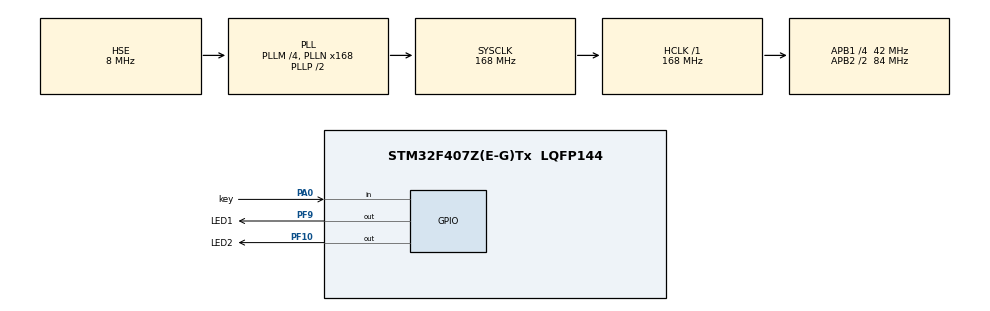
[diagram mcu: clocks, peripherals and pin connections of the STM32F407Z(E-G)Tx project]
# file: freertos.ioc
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FREERTOS.Queues01=message,16,uint16_t,0,Dynamic,NULL,NULL
FREERTOS.Tasks01=key,24,128,keyfunction,Default,NULL,Dynamic,NULL,NULL;led,8,128,ledfunction,Default,NULL,Dynamic,NULL,NULL
Mcu.Family=STM32F4
Mcu.Name=STM32F407Z(E-G)Tx
Mcu.Package=LQFP144
NVIC.PriorityGroup=NVIC_PRIORITYGROUP_4
NVIC.TIM7_IRQn=true\:0\:0\:false\:false\:true\:false\:false\:true
NVIC.TimeBase=TIM7_IRQn
NVIC.TimeBaseIP=TIM7
PA0-WKUP.GPIO_Label=key
PA0-WKUP.Signal=GPIO_Input
PA13.Mode=Serial_Wire
PA13.Signal=SYS_JTMS-SWDIO
PA14.Mode=Serial_Wire
PA14.Signal=SYS_JTCK-SWCLK
PF10.GPIO_Label=LED2
PF10.Signal=GPIO_Output
PF9.GPIO_Label=LED1
PF9.Signal=GPIO_Output
PH0-OSC_IN.Mode=HSE-External-Oscillator
PH0-OSC_IN.Signal=RCC_OSC_IN
PH1-OSC_OUT.Mode=HSE-External-Oscillator
PH1-OSC_OUT.Signal=RCC_OSC_OUT
ProjectManager.HeapSize=0x200
ProjectManager.StackSize=0x400
ProjectManager.TargetToolchain=STM32CubeIDE
RCC.48MHZClocksFreq_Value=84000000
RCC.AHBFreq_Value=168000000
RCC.APB1CLKDivider=RCC_HCLK_DIV4
RCC.APB1Freq_Value=42000000
RCC.APB1TimFreq_Value=84000000
RCC.APB2CLKDivider=RCC_HCLK_DIV2
RCC.APB2Freq_Value=84000000
RCC.APB2TimFreq_Value=168000000
RCC.CortexFreq_Value=168000000
RCC.HCLKFreq_Value=168000000
RCC.HSE_VALUE=8000000
RCC.HSI_VALUE=16000000
RCC.LSE_VALUE=32768
RCC.PLLM=4
RCC.PLLN=168
RCC.PLLSourceVirtual=RCC_PLLSOURCE_HSE
RCC.SYSCLKFreq_VALUE=168000000
RCC.SYSCLKSource=RCC_SYSCLKSOURCE_PLLCLK
RCC.VCOOutputFreq_Value=336000000
VP_FREERTOS_VS_CMSIS_V2.Mode=CMSIS_V2
VP_RTC_VS_RTC_Activate.Mode=RTC_Enabled
VP_SYS_VS_tim7.Mode=TIM7
board=custom

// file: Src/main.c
/* USER CODE BEGIN Header */
/**
  ******************************************************************************
  * @file           : main.c
  * @brief          : Main program body
  ******************************************************************************
  * @attention
  *
  * <h2><center>&copy; Copyright (c) 2019 STMicroelectronics.
  * All rights reserved.</center></h2>
  *
  * This software component is licensed by ST under Ultimate Liberty license
  * SLA0044, the "License"; You may not use this file except in compliance with
  * the License. You may obtain a copy of the License at:
  *                             www.st.com/SLA0044
  *
  ******************************************************************************
  */
/* USER CODE END Header */

#include "main.h"
#include "cmsis_os.h"
#include "rtc.h"
#include "gpio.h"

void SystemClock_Config(void);
void MX_FREERTOS_Init(void);

int main(void)
{

  /* MCU Configuration--------------------------------------------------------*/

  /* Reset of all peripherals, Initializes the Flash interface and the Systick. */
  HAL_Init();

  /* Configure the system clock */
  SystemClock_Config();

  /* Initialize all configured peripherals */
  MX_GPIO_Init();
  MX_RTC_Init();

  /* Call init function for freertos objects (in freertos.c) */
  MX_FREERTOS_Init();

  /* Start scheduler */
  osKernelStart();

  /* We should never get here as control is now taken by the scheduler */

  /* Infinite loop */
  while (1)
  {

  }
}

void SystemClock_Config(void)
{
  RCC_OscInitTypeDef RCC_OscInitStruct = {0};
  RCC_ClkInitTypeDef RCC_ClkInitStruct = {0};
  RCC_PeriphCLKInitTypeDef PeriphClkInitStruct = {0};

  /** Configure the main internal regulator output voltage
  */
  __HAL_RCC_PWR_CLK_ENABLE();
  __HAL_PWR_VOLTAGESCALING_CONFIG(PWR_REGULATOR_VOLTAGE_SCALE1);
  /** Initializes the CPU, AHB and APB busses clocks
  */
  RCC_OscInitStruct.OscillatorType = RCC_OSCILLATORTYPE_LSI|RCC_OSCILLATORTYPE_HSE;
  RCC_OscInitStruct.HSEState = RCC_HSE_ON;
  RCC_OscInitStruct.LSIState = RCC_LSI_ON;
  RCC_OscInitStruct.PLL.PLLState = RCC_PLL_ON;
  RCC_OscInitStruct.PLL.PLLSource = RCC_PLLSOURCE_HSE;
  RCC_OscInitStruct.PLL.PLLM = 4;
  RCC_OscInitStruct.PLL.PLLN = 168;
  RCC_OscInitStruct.PLL.PLLP = RCC_PLLP_DIV2;
  RCC_OscInitStruct.PLL.PLLQ = 4;
  if (HAL_RCC_OscConfig(&RCC_OscInitStruct) != HAL_OK)
  {
    Error_Handler();
  }
  /** Initializes the CPU, AHB and APB busses clocks
  */
  RCC_ClkInitStruct.ClockType = RCC_CLOCKTYPE_HCLK|RCC_CLOCKTYPE_SYSCLK
                              |RCC_CLOCKTYPE_PCLK1|RCC_CLOCKTYPE_PCLK2;
  RCC_ClkInitStruct.SYSCLKSource = RCC_SYSCLKSOURCE_PLLCLK;
  RCC_ClkInitStruct.AHBCLKDivider = RCC_SYSCLK_DIV1;
  RCC_ClkInitStruct.APB1CLKDivider = RCC_HCLK_DIV4;
  RCC_ClkInitStruct.APB2CLKDivider = RCC_HCLK_DIV2;

  if (HAL_RCC_ClockConfig(&RCC_ClkInitStruct, FLASH_LATENCY_5) != HAL_OK)
  {
    Error_Handler();
  }
  PeriphClkInitStruct.PeriphClockSelection = RCC_PERIPHCLK_RTC;
  PeriphClkInitStruct.RTCClockSelection = RCC_RTCCLKSOURCE_LSI;
  if (HAL_RCCEx_PeriphCLKConfig(&PeriphClkInitStruct) != HAL_OK)
  {
    Error_Handler();
  }
}

void HAL_TIM_PeriodElapsedCallback(TIM_HandleTypeDef *htim)
{
  if (htim->Instance == TIM7) {
    HAL_IncTick();
  }
}

void Error_Handler(void)
{
}

/************************ (C) COPYRIGHT STMicroelectronics *****END OF FILE****/

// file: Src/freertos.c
/* USER CODE BEGIN Header */
/**
  ******************************************************************************
  * File Name          : freertos.c
  * Description        : Code for freertos applications
  ******************************************************************************
  * @attention
  *
  * <h2><center>&copy; Copyright (c) 2019 STMicroelectronics.
  * All rights reserved.</center></h2>
  *
  * This software component is licensed by ST under Ultimate Liberty license
  * SLA0044, the "License"; You may not use this file except in compliance with
  * the License. You may obtain a copy of the License at:
  *                             www.st.com/SLA0044
  *
  ******************************************************************************
  */
/* USER CODE END Header */

#include "FreeRTOS.h"
#include "task.h"
#include "main.h"
#include "cmsis_os.h"

osThreadId_t keyHandle;
osThreadId_t led1Handle;
osThreadId_t led2Handle;
osMessageQueueId_t messageHandle;

void keyfunction(void *argument); // for v2
void led1function(void *argument); // for v2
void led2function(void *argument); // for v2

void MX_FREERTOS_Init(void); /* (MISRA C 2004 rule 8.1) */

void MX_FREERTOS_Init(void) {
osKernelInitialize(); // Initialize CMSIS-RTOS

  /* Create the queue(s) */
  /* definition and creation of message */
  const osMessageQueueAttr_t message_attributes = {
    .name = "message"
  };
  messageHandle = osMessageQueueNew (16, sizeof(uint16_t), &message_attributes);

  /* Create the thread(s) */
  /* definition and creation of key */
  const osThreadAttr_t key_attributes = {
    .name = "key",
    .priority = (osPriority_t) osPriorityNormal,
    .stack_size = 512
  };
  keyHandle = osThreadNew(keyfunction, NULL, &key_attributes);

  /* definition and creation of led1 */
  const osThreadAttr_t led1_attributes = {
    .name = "led1",
    .priority = (osPriority_t) osPriorityLow,
    .stack_size = 512
  };
  led1Handle = osThreadNew(led1function, NULL, &led1_attributes);

  /* definition and creation of led2 */
  const osThreadAttr_t led2_attributes = {
    .name = "led2",
    .priority = (osPriority_t) osPriorityLow,
    .stack_size = 512
  };
  led2Handle = osThreadNew(led2function, NULL, &led2_attributes);

}

void keyfunction(void *argument)
{

  /* USER CODE BEGIN keyfunction */
	uint16_t p;
  /* Infinite loop */
for(;;)
{p = 1;
osMessageQueuePut(messageHandle,(void *)&p,0,0);
osDelay(500);
p= 2;
osMessageQueuePut(messageHandle,(void *)&p,0,0);
osDelay(500);
}

  /* USER CODE END keyfunction */
}

void led1function(void *argument)
{
  /* USER CODE BEGIN led1function */
  /* Infinite loop */
	uint16_t p;
	osStatus_t sta;
	for(;;)
	{
  	sta = osMessageQueueGet (messageHandle, (void *)&p, 0, 100);
	if(sta == osOK)
	{

	if(p == 1){
		HAL_GPIO_WritePin(GPIOF,GPIO_PIN_9,GPIO_PIN_SET);
		HAL_GPIO_WritePin(GPIOF,GPIO_PIN_10,GPIO_PIN_RESET);
		}
	else
	{
	HAL_GPIO_WritePin(GPIOF,GPIO_PIN_9,GPIO_PIN_RESET);
	HAL_GPIO_WritePin(GPIOF,GPIO_PIN_10,GPIO_PIN_SET);
	  }
	}
	osDelay(1);
	}
  /* USER CODE END led1function */
}

void led2function(void *argument)
{
	for(;;)
	{
	osDelay(1);
	}
}

/************************ (C) COPYRIGHT STMicroelectronics *****END OF FILE****/
